# MKL34Z4 register map
Vendor: Freescale Semiconductor, Inc.; File version: 1.6
CPU: CM0PLUS r0p0, little endian, no MPU, no FPU, 0x2 interrupt priority bits, 0x0 interrupts
Registers are 32-bit, read-write, reset 0x0 unless marked. A register's access mark holds for its fields unless they carry their own. Offsets are from the block's base; [hi:lo] are bit positions; {n}, {i} and the like mark numbered series; 'fields as' and 'values as' point back to an identical list.

## PORTE — Pin Control and Interrupts
Base 0x4004D000; register names take the prefix PORTE_
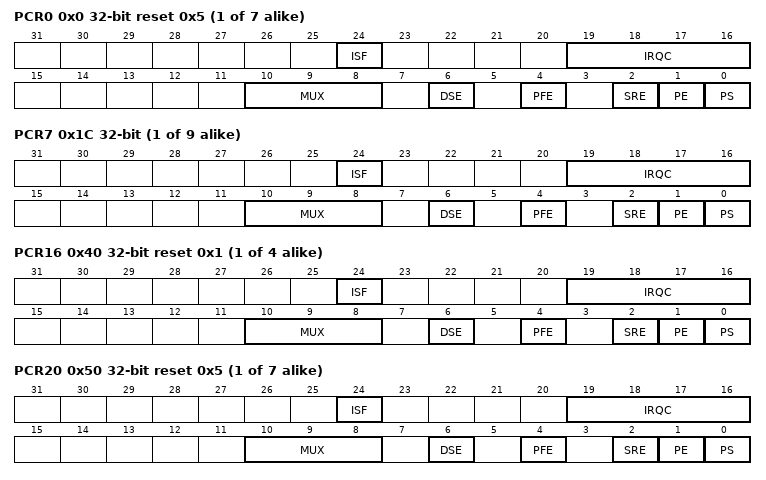
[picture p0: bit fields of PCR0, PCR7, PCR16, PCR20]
{0x0+4i} PCR{i} reset 0x5 (i=0..6) — Pin Control Register n
  [24] ISF — Interrupt Status Flag
    0=Configured interrupt is not detected; 1=Configured interrupt is detected. If the pin is configured to generate a DMA request, then the corresponding flag will be cleared automatically at the completion of the requested DMA transfer. Otherwise, the flag remains set until a logic one is written to the flag. If the pin is configured for a level sensitive interrupt and the pin remains asserted, then the flag is set again immediately after it is cleared.
  [19:16] IRQC — Interrupt Configuration
    0=Interrupt/DMA request disabled; 1=DMA request on rising edge; 2=DMA request on falling edge; 3=DMA request on either edge; 8=Interrupt when logic zero; 9=Interrupt on rising edge; 10=Interrupt on falling edge; 11=Interrupt on either edge; 12=Interrupt when logic one
  [10:8] MUX — Pin Mux Control
    0=Pin disabled (analog); 1=Alternative 1 (GPIO); {v}=Alternative {v} (chip-specific) (v=2..7)
  [6] DSE ro — Drive Strength Enable
    0=Low drive strength is configured on the corresponding pin, if pin is configured as a digital output; 1=High drive strength is configured on the corresponding pin, if pin is configured as a digital output
  [4] PFE ro — Passive Filter Enable
    0=Passive input filter is disabled on the corresponding pin; 1=Passive input filter is enabled on the corresponding pin, if the pin is configured as a digital input. Refer to the device data sheet for filter characteristics.
  [2] SRE — Slew Rate Enable
    0=Fast slew rate is configured on the corresponding pin, if the pin is configured as a digital output; 1=Slow slew rate is configured on the corresponding pin, if the pin is configured as a digital output
  [1] PE — Pull Enable
    0=Internal pullup or pulldown resistor is not enabled on the corresponding pin; 1=Internal pullup or pulldown resistor is enabled on the corresponding pin, if the pin is configured as a digital input
  [0] PS — Pull Select
    0=Internal pulldown resistor is enabled on the corresponding pin, if the corresponding Port Pull Enable field is set; 1=Internal pullup resistor is enabled on the corresponding pin, if the corresponding Port Pull Enable field is set
{0x0+4i} PCR{i} (i=7..15) — Pin Control Register n
  [24] ISF — Interrupt Status Flag
    values as PCR0.ISF
  [19:16] IRQC — Interrupt Configuration
    values as PCR0.IRQC
  [10:8] MUX — Pin Mux Control
    values as PCR0.MUX
  [6] DSE ro — Drive Strength Enable
    values as PCR0.DSE
  [4] PFE ro — Passive Filter Enable
    values as PCR0.PFE
  [2] SRE ro — Slew Rate Enable
    values as PCR0.SRE
  [1] PE ro — Pull Enable
    values as PCR0.PE
  [0] PS ro — Pull Select
    values as PCR0.PS
{0x0+4i} PCR{i} reset 0x1 (i=16..19) — Pin Control Register n
  fields as PCR0
{0x0+4i} PCR{i} reset 0x5 (i=20..26) — Pin Control Register n
  fields as PCR0
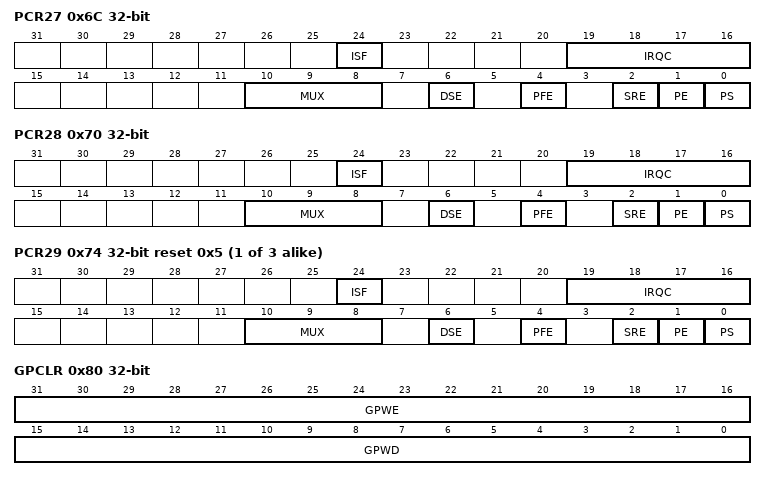
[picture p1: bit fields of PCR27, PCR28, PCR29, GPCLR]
0x6C PCR27 — Pin Control Register n
  fields as PCR7
0x70 PCR28 — Pin Control Register n
  fields as PCR7
{0x0+4i} PCR{i} reset 0x5 (i=29..31) — Pin Control Register n
  fields as PCR0
0x80 GPCLR wo — Global Pin Control Low Register
  [31:16] GPWE — Global Pin Write Enable
    0=Corresponding Pin Control Register is not updated with the value in GPWD; 1=Corresponding Pin Control Register is updated with the value in GPWD
  [15:0] GPWD — Global Pin Write Data
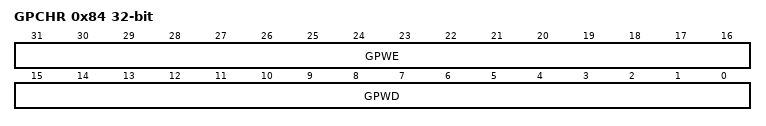
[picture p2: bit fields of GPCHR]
0x84 GPCHR wo — Global Pin Control High Register
  fields as GPCLR
0xA0 ISFR — Interrupt Status Flag Register
  [31:0] ISF — Interrupt Status Flag
    values as PCR0.ISF
